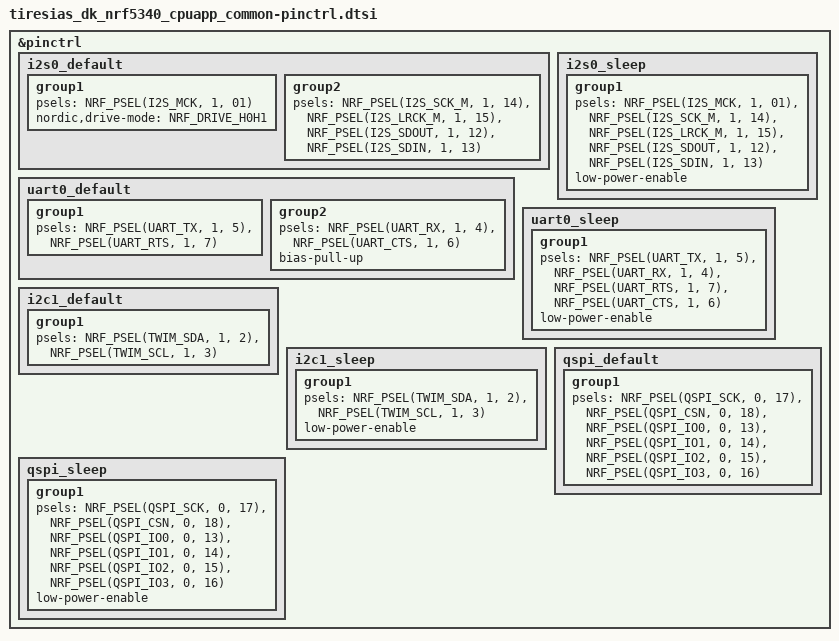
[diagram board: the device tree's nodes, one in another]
/*
 * Copyright (c) 2022 Nordic Semiconductor ASA
 *
 * SPDX-License-Identifier: Apache-2.0
 */

&pinctrl {
	i2s0_default: i2s0_default {
		group1 {
      			psels = <NRF_PSEL(I2S_MCK, 1, 01)>;
      			nordic,drive-mode = <NRF_DRIVE_H0H1>;
    		};
    		group2 {
			psels = <NRF_PSEL(I2S_SCK_M, 1, 14)>,
				<NRF_PSEL(I2S_LRCK_M, 1, 15)>,
				<NRF_PSEL(I2S_SDOUT, 1, 12)>,
				<NRF_PSEL(I2S_SDIN, 1, 13)>;
		};
	};

	i2s0_sleep: i2s0_sleep {
		group1 {
			psels = <NRF_PSEL(I2S_MCK, 1, 01)>,
        			<NRF_PSEL(I2S_SCK_M, 1, 14)>,
				<NRF_PSEL(I2S_LRCK_M, 1, 15)>,
				<NRF_PSEL(I2S_SDOUT, 1, 12)>,
				<NRF_PSEL(I2S_SDIN, 1, 13)>;
			low-power-enable;
		};
	};

	uart0_default: uart0_default {
		group1 {
			psels = <NRF_PSEL(UART_TX, 1, 5)>,
				<NRF_PSEL(UART_RTS, 1, 7)>;
		};
		group2 {
			psels = <NRF_PSEL(UART_RX, 1, 4)>,
				<NRF_PSEL(UART_CTS, 1, 6)>;
			bias-pull-up;
		};
	};

	uart0_sleep: uart0_sleep {
		group1 {
			psels = <NRF_PSEL(UART_TX, 1, 5)>,
				<NRF_PSEL(UART_RX, 1, 4)>,
				<NRF_PSEL(UART_RTS, 1, 7)>,
				<NRF_PSEL(UART_CTS, 1, 6)>;
			low-power-enable;
		};
	};

	i2c1_default: i2c1_default {
		group1 {
			psels = <NRF_PSEL(TWIM_SDA, 1, 2)>,
				<NRF_PSEL(TWIM_SCL, 1, 3)>;
		};
	};

	i2c1_sleep: i2c1_sleep {
		group1 {
			psels = <NRF_PSEL(TWIM_SDA, 1, 2)>,
				<NRF_PSEL(TWIM_SCL, 1, 3)>;
			low-power-enable;
		};
	};

	/* QSPI pin configuration for external flash */
	qspi_default: qspi_default {
		group1 {
			psels = <NRF_PSEL(QSPI_SCK, 0, 17)>,
				<NRF_PSEL(QSPI_CSN, 0, 18)>,
				<NRF_PSEL(QSPI_IO0, 0, 13)>,
				<NRF_PSEL(QSPI_IO1, 0, 14)>,
				<NRF_PSEL(QSPI_IO2, 0, 15)>,
				<NRF_PSEL(QSPI_IO3, 0, 16)>;
		};
	};

	qspi_sleep: qspi_sleep {
		group1 {
			psels = <NRF_PSEL(QSPI_SCK, 0, 17)>,
				<NRF_PSEL(QSPI_CSN, 0, 18)>,
				<NRF_PSEL(QSPI_IO0, 0, 13)>,
				<NRF_PSEL(QSPI_IO1, 0, 14)>,
				<NRF_PSEL(QSPI_IO2, 0, 15)>,
				<NRF_PSEL(QSPI_IO3, 0, 16)>;
			low-power-enable;
		};
	};
};
